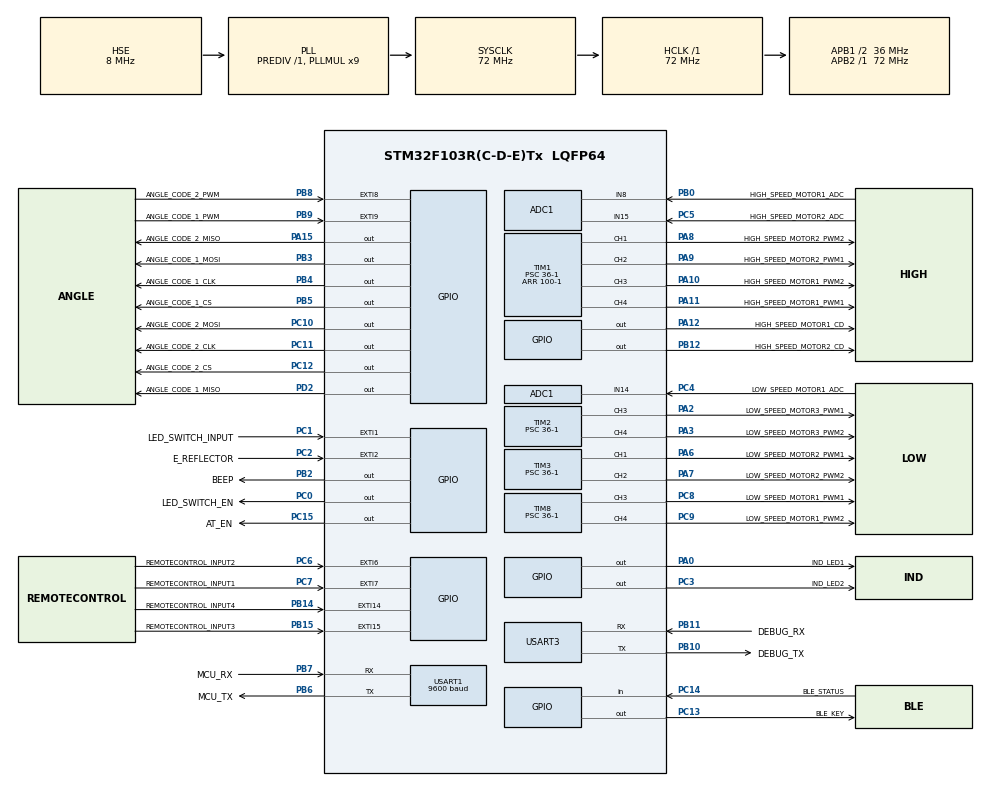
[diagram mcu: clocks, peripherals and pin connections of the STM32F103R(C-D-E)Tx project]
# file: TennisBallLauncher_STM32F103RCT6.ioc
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ADC1.Channel-11\#ChannelRegularConversion=ADC_CHANNEL_8
ADC1.Channel-12\#ChannelRegularConversion=ADC_CHANNEL_14
ADC1.Channel-13\#ChannelRegularConversion=ADC_CHANNEL_15
ADC1.ContinuousConvMode=DISABLE
ADC1.NbrOfConversion=3
ADC1.NbrOfConversionFlag=1
ADC1.Rank-11\#ChannelRegularConversion=1
ADC1.Rank-12\#ChannelRegularConversion=2
ADC1.Rank-13\#ChannelRegularConversion=3
ADC1.SamplingTime-11\#ChannelRegularConversion=ADC_SAMPLETIME_28CYCLES_5
ADC1.SamplingTime-12\#ChannelRegularConversion=ADC_SAMPLETIME_28CYCLES_5
ADC1.SamplingTime-13\#ChannelRegularConversion=ADC_SAMPLETIME_28CYCLES_5
ADC1.master=1
Dma.ADC1.1.Direction=DMA_PERIPH_TO_MEMORY
Dma.ADC1.1.Instance=DMA1_Channel1
Dma.ADC1.1.MemDataAlignment=DMA_MDATAALIGN_WORD
Dma.ADC1.1.MemInc=DMA_MINC_ENABLE
Dma.ADC1.1.Mode=DMA_CIRCULAR
Dma.ADC1.1.PeriphDataAlignment=DMA_PDATAALIGN_WORD
Dma.ADC1.1.PeriphInc=DMA_PINC_DISABLE
Dma.ADC1.1.Priority=DMA_PRIORITY_MEDIUM
Dma.Request0=USART1_RX
Dma.Request1=ADC1
Dma.USART1_RX.0.Direction=DMA_PERIPH_TO_MEMORY
Dma.USART1_RX.0.Instance=DMA1_Channel5
Dma.USART1_RX.0.MemDataAlignment=DMA_MDATAALIGN_BYTE
Dma.USART1_RX.0.MemInc=DMA_MINC_ENABLE
Dma.USART1_RX.0.Mode=DMA_CIRCULAR
Dma.USART1_RX.0.PeriphDataAlignment=DMA_PDATAALIGN_BYTE
Dma.USART1_RX.0.PeriphInc=DMA_PINC_DISABLE
Dma.USART1_RX.0.Priority=DMA_PRIORITY_LOW
Mcu.Family=STM32F1
Mcu.Name=STM32F103R(C-D-E)Tx
Mcu.Package=LQFP64
NVIC.DMA1_Channel1_IRQn=true\:0\:0\:false\:false\:true\:false\:true\:true
NVIC.DMA1_Channel5_IRQn=true\:0\:0\:false\:false\:true\:false\:true\:true
NVIC.EXTI15_10_IRQn=true\:0\:0\:false\:false\:true\:true\:true\:true
NVIC.EXTI1_IRQn=true\:0\:0\:false\:false\:true\:true\:true\:true
NVIC.EXTI2_IRQn=true\:0\:0\:false\:false\:true\:true\:true\:true
NVIC.EXTI9_5_IRQn=true\:0\:0\:false\:false\:true\:true\:true\:true
NVIC.PriorityGroup=NVIC_PRIORITYGROUP_4
NVIC.TIM6_IRQn=true\:0\:0\:false\:false\:true\:true\:true\:true
NVIC.TIM7_IRQn=true\:0\:0\:false\:false\:true\:true\:true\:true
NVIC.USART1_IRQn=true\:0\:0\:false\:false\:true\:true\:true\:true
PA0-WKUP.GPIO_Label=IND_LED1
PA0-WKUP.Signal=GPIO_Output
PA10.GPIO_Label=HIGH_SPEED_MOTOR1_PWM2
PA10.Signal=S_TIM1_CH3
PA11.GPIO_Label=HIGH_SPEED_MOTOR1_PWM1
PA11.Signal=S_TIM1_CH4
PA12.GPIO_Label=HIGH_SPEED_MOTOR1_CD
PA12.Signal=GPIO_Output
PA13.Mode=Serial_Wire
PA13.Signal=SYS_JTMS-SWDIO
PA14.Mode=Serial_Wire
PA14.Signal=SYS_JTCK-SWCLK
PA15.GPIO_Label=ANGLE_CODE_2_MISO
PA15.Signal=GPIO_Output
PA2.GPIO_Label=LOW_SPEED_MOTOR3_PWM1
PA2.Signal=S_TIM2_CH3
PA3.GPIO_Label=LOW_SPEED_MOTOR3_PWM2
PA3.Signal=S_TIM2_CH4
PA6.GPIO_Label=LOW_SPEED_MOTOR2_PWM1
PA6.Signal=S_TIM3_CH1
PA7.GPIO_Label=LOW_SPEED_MOTOR2_PWM2
PA7.Signal=S_TIM3_CH2
PA8.GPIO_Label=HIGH_SPEED_MOTOR2_PWM2
PA8.Signal=S_TIM1_CH1
PA9.GPIO_Label=HIGH_SPEED_MOTOR2_PWM1
PA9.Signal=S_TIM1_CH2
PB0.GPIO_Label=HIGH_SPEED_MOTOR1_ADC
PB0.Signal=ADCx_IN8
PB10.GPIO_Label=DEBUG_TX
PB10.Mode=Asynchronous
PB10.Signal=USART3_TX
PB11.GPIO_Label=DEBUG_RX
PB11.Mode=Asynchronous
PB11.Signal=USART3_RX
PB12.GPIO_Label=HIGH_SPEED_MOTOR2_CD
PB12.Signal=GPIO_Output
PB14.GPIO_Label=REMOTECONTROL_INPUT4
PB14.GPIO_PuPd=GPIO_PULLDOWN
PB14.Signal=GPXTI14
PB15.GPIO_Label=REMOTECONTROL_INPUT3
PB15.GPIO_PuPd=GPIO_PULLDOWN
PB15.Signal=GPXTI15
PB2.GPIO_Label=BEEP
PB2.Signal=GPIO_Output
PB3.GPIO_Label=ANGLE_CODE_1_MOSI
PB3.Signal=GPIO_Output
PB4.GPIO_Label=ANGLE_CODE_1_CLK
PB4.Signal=GPIO_Output
PB5.GPIO_Label=ANGLE_CODE_1_CS
PB5.Signal=GPIO_Output
PB6.GPIO_Label=MCU_TX
PB6.Mode=Asynchronous
PB6.Signal=USART1_TX
PB7.GPIO_Label=MCU_RX
PB7.Mode=Asynchronous
PB7.Signal=USART1_RX
PB8.GPIO_Label=ANGLE_CODE_2_PWM
PB8.GPIO_ModeDefaultEXTI=GPIO_MODE_IT_RISING_FALLING
PB8.Signal=GPXTI8
PB9.GPIO_Label=ANGLE_CODE_1_PWM
PB9.GPIO_ModeDefaultEXTI=GPIO_MODE_IT_RISING_FALLING
PB9.Signal=GPXTI9
PC0.GPIO_Label=LED_SWITCH_EN
PC0.Signal=GPIO_Output
PC1.GPIO_Label=LED_SWITCH_INPUT
PC1.GPIO_ModeDefaultEXTI=GPIO_MODE_IT_FALLING
PC1.GPIO_PuPd=GPIO_PULLUP
PC1.Signal=GPXTI1
PC10.GPIO_Label=ANGLE_CODE_2_MOSI
PC10.Signal=GPIO_Output
PC11.GPIO_Label=ANGLE_CODE_2_CLK
PC11.Signal=GPIO_Output
PC12.GPIO_Label=ANGLE_CODE_2_CS
PC12.Signal=GPIO_Output
PC13-TAMPER-RTC.GPIO_Label=BLE_KEY
PC13-TAMPER-RTC.PinState=GPIO_PIN_SET
PC13-TAMPER-RTC.Signal=GPIO_Output
PC14-OSC32_IN.GPIO_Label=BLE_STATUS
PC14-OSC32_IN.Signal=GPIO_Input
PC15-OSC32_OUT.GPIO_Label=AT_EN
PC15-OSC32_OUT.PinState=GPIO_PIN_SET
PC15-OSC32_OUT.Signal=GPIO_Output
PC2.GPIO_Label=E_REFLECTOR
PC2.GPIO_ModeDefaultEXTI=GPIO_MODE_IT_RISING
PC2.GPIO_PuPd=GPIO_PULLDOWN
PC2.Signal=GPXTI2
PC3.GPIO_Label=IND_LED2
PC3.Signal=GPIO_Output
PC4.GPIO_Label=LOW_SPEED_MOTOR1_ADC
PC4.Signal=ADCx_IN14
PC5.GPIO_Label=HIGH_SPEED_MOTOR2_ADC
PC5.Signal=ADCx_IN15
PC6.GPIO_Label=REMOTECONTROL_INPUT2
PC6.GPIO_PuPd=GPIO_PULLDOWN
PC6.Signal=GPXTI6
PC7.GPIO_Label=REMOTECONTROL_INPUT1
PC7.GPIO_PuPd=GPIO_PULLDOWN
PC7.Signal=GPXTI7
PC8.GPIO_Label=LOW_SPEED_MOTOR1_PWM1
PC8.Signal=S_TIM8_CH3
PC9.GPIO_Label=LOW_SPEED_MOTOR1_PWM2
PC9.Signal=S_TIM8_CH4
PD0-OSC_IN.Mode=HSE-External-Oscillator
PD0-OSC_IN.Signal=RCC_OSC_IN
PD1-OSC_OUT.Mode=HSE-External-Oscillator
PD1-OSC_OUT.Signal=RCC_OSC_OUT
PD2.GPIO_Label=ANGLE_CODE_1_MISO
PD2.Signal=GPIO_Output
ProjectManager.HeapSize=0x400
ProjectManager.StackSize=0x1500
ProjectManager.TargetToolchain=MDK-ARM V5.32
RCC.ADCPresc=RCC_ADCPCLK2_DIV6
RCC.AHBFreq_Value=72000000
RCC.APB1CLKDivider=RCC_HCLK_DIV2
RCC.APB1Freq_Value=36000000
RCC.APB1TimFreq_Value=72000000
RCC.APB2Freq_Value=72000000
RCC.APB2TimFreq_Value=72000000
RCC.HCLKFreq_Value=72000000
RCC.PLLMUL=RCC_PLL_MUL9
RCC.PLLSourceVirtual=RCC_PLLSOURCE_HSE
RCC.SYSCLKFreq_VALUE=72000000
RCC.SYSCLKSource=RCC_SYSCLKSOURCE_PLLCLK
RCC.USBFreq_Value=72000000
SH.ADCx_IN14.0=ADC1_IN14,IN14
SH.ADCx_IN15.0=ADC1_IN15,IN15
SH.ADCx_IN8.0=ADC1_IN8,IN8
SH.S_TIM1_CH1.0=TIM1_CH1,PWM Generation1 CH1
SH.S_TIM1_CH2.0=TIM1_CH2,PWM Generation2 CH2
SH.S_TIM1_CH3.0=TIM1_CH3,PWM Generation3 CH3
SH.S_TIM1_CH4.0=TIM1_CH4,PWM Generation4 CH4
SH.S_TIM2_CH3.0=TIM2_CH3,PWM Generation3 CH3
SH.S_TIM2_CH4.0=TIM2_CH4,PWM Generation4 CH4
SH.S_TIM3_CH1.0=TIM3_CH1,PWM Generation1 CH1
SH.S_TIM3_CH2.0=TIM3_CH2,PWM Generation2 CH2
SH.S_TIM8_CH3.0=TIM8_CH3,PWM Generation3 CH3
SH.S_TIM8_CH4.0=TIM8_CH4,PWM Generation4 CH4
TIM1.Channel-Input_Capture3_from_TI3=TIM_CHANNEL_3
TIM1.Channel-Input_Capture3_from_TI4_63=TIM_CHANNEL_3
TIM1.Channel-Input_Capture4_from_TI4=TIM_CHANNEL_4
TIM1.Channel-PWM\ Generation1\ CH1=TIM_CHANNEL_1
TIM1.Channel-PWM\ Generation2\ CH2=TIM_CHANNEL_2
TIM1.Channel-PWM\ Generation3\ CH3=TIM_CHANNEL_3
TIM1.Channel-PWM\ Generation4\ CH4=TIM_CHANNEL_4
TIM1.Period=100-1
TIM1.Prescaler=36-1
TIM2.Channel-PWM\ Generation3\ CH3=TIM_CHANNEL_3
TIM2.Channel-PWM\ Generation4\ CH4=TIM_CHANNEL_4
TIM2.Period=100-1
TIM2.Prescaler=36-1
TIM3.Channel-PWM\ Generation1\ CH1=TIM_CHANNEL_1
TIM3.Channel-PWM\ Generation2\ CH2=TIM_CHANNEL_2
TIM3.Period=100-1
TIM3.Prescaler=36-1
TIM6.Period=5000-1
TIM6.Prescaler=72-1
TIM7.Period=1000-1
TIM7.Prescaler=72-1
TIM8.Channel-PWM\ Generation3\ CH3=TIM_CHANNEL_3
TIM8.Channel-PWM\ Generation4\ CH4=TIM_CHANNEL_4
TIM8.Period=100-1
TIM8.Prescaler=36-1
USART1.BaudRate=9600
USART1.VirtualMode=VM_ASYNC
USART3.VirtualMode=VM_ASYNC
VP_TIM1_VS_ClockSourceINT.Mode=Internal
VP_TIM2_VS_ClockSourceINT.Mode=Internal
VP_TIM3_VS_ClockSourceINT.Mode=Internal
VP_TIM6_VS_ClockSourceINT.Mode=Enable_Timer
VP_TIM7_VS_ClockSourceINT.Mode=Enable_Timer
board=custom

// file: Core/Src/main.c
/* USER CODE BEGIN Header */
/**
 ******************************************************************************
 * @file           : main.c
 * @brief          : Main program body
 ******************************************************************************
 * @attention
 *
 * Copyright (c) 2024 STMicroelectronics.
 * All rights reserved.
 *
 * This software is licensed under terms that can be found in the LICENSE file
 * in the root directory of this software component.
 * If no LICENSE file comes with this software, it is provided AS-IS.
 *
 ******************************************************************************
 */
/* USER CODE END Header */
#include "main.h"
#include "adc.h"
#include "dma.h"
#include "tim.h"
#include "usart.h"
#include "gpio.h"

/* USER CODE BEGIN Includes */
#include "usart.h"
#include "myApp.h"
#include "flash.h"
#include "myBle.h"
#include "myBeep.h"

//#define log_debug printf()
/* USER CODE END Includes */

void SystemClock_Config(void);

int main(void)
{

  /* USER CODE BEGIN 1 */
  // HAL_Delay(5000); //
  /* USER CODE END 1 */

  /* MCU Configuration--------------------------------------------------------*/

  /* Reset of all peripherals, Initializes the Flash interface and the Systick. */
  HAL_Init();

  /* Configure the system clock */
  SystemClock_Config();

  /* Initialize all configured peripherals */
  MX_GPIO_Init();
  MX_DMA_Init();
  MX_ADC1_Init();
  MX_TIM1_Init();
  MX_TIM2_Init();
  MX_TIM3_Init();
  MX_USART1_UART_Init();
  MX_USART3_UART_Init();
	// debug_uart_printf("111111111 Running......\r\n");
  MX_TIM8_Init();//debug_uart_printf("2222222 Running......\r\n");
  MX_TIM7_Init();//debug_uart_printf("3333333333 Running......\r\n");
  MX_TIM6_Init();//debug_uart_printf("44444444 Running......\r\n");

  /* USER CODE BEGIN 2 */
  HAL_Delay(5000); //
  myAppTaskInit();
  debug_uart_printf("TennisBalllLauncher Running......\r\n");

//		uint8_t name_data[]="01250841180";
//	FLASH_EEPROM_Write_test(name_data,strlen(name_data),Flash_User_Name_ID);
	ble_data_init();//�����㲥name��ȡ

//	uint8_t name_data[]="01250841180";
//	FLASH_EEPROM_Write_test(name_data,strlen(name_data),Flash_User_Name_ID);

	//printf("flash_read = %d\r\n",FLASH_EEPROM_Read());

//	uint32_t rer =34;
//	uint8_t senddata[8]={1,2,3,4,5,6,7,8};
//	debug_uart_printf("flash_write\r\n");
//
//	FLASH_EEPROM_Write_test(senddata,5,Flash_User_Name_ID);
//	//FLASH_EEPROM_Write(rer);
//	//HAL_Delay(1000);
//	uint8_t dataew[100]={0};
//myBleAT_L();	ble_at_cmd_call_fun(AT_ADVI);
//ble_at_cmd_call_fun(AT_SETNAME);
//	FLASH_EEPROM_Read(dataew,8,USER_CUSTOM_DATA_FLASH);
//	///printf("flash_read22 = %d\r\n",FLASH_EEPROM_Read());
//	for(int i=0;i<8;i++)
//	{
//		debug_uart_printf(" %02x ",dataew[i]);
//	}
//

  /* USER CODE END 2 */
//test_fun();
  /* Infinite loop */
  while (1)
  {
    /* USER CODE BEGIN 3 */
     myAppTaskHandle();
  }
  /* USER CODE END 3 */
}

void SystemClock_Config(void)
{
  RCC_OscInitTypeDef RCC_OscInitStruct = {0};
  RCC_ClkInitTypeDef RCC_ClkInitStruct = {0};
  RCC_PeriphCLKInitTypeDef PeriphClkInit = {0};

  /** Initializes the RCC Oscillators according to the specified parameters
  * in the RCC_OscInitTypeDef structure.
  */
  RCC_OscInitStruct.OscillatorType = RCC_OSCILLATORTYPE_HSE;
  RCC_OscInitStruct.HSEState = RCC_HSE_ON;
  RCC_OscInitStruct.HSEPredivValue = RCC_HSE_PREDIV_DIV1;
  RCC_OscInitStruct.HSIState = RCC_HSI_ON;
  RCC_OscInitStruct.PLL.PLLState = RCC_PLL_ON;
  RCC_OscInitStruct.PLL.PLLSource = RCC_PLLSOURCE_HSE;
  RCC_OscInitStruct.PLL.PLLMUL = RCC_PLL_MUL9;
  if (HAL_RCC_OscConfig(&RCC_OscInitStruct) != HAL_OK)
  {
    Error_Handler();
  }

  /** Initializes the CPU, AHB and APB buses clocks
  */
  RCC_ClkInitStruct.ClockType = RCC_CLOCKTYPE_HCLK|RCC_CLOCKTYPE_SYSCLK
                              |RCC_CLOCKTYPE_PCLK1|RCC_CLOCKTYPE_PCLK2;
  RCC_ClkInitStruct.SYSCLKSource = RCC_SYSCLKSOURCE_PLLCLK;
  RCC_ClkInitStruct.AHBCLKDivider = RCC_SYSCLK_DIV1;
  RCC_ClkInitStruct.APB1CLKDivider = RCC_HCLK_DIV2;
  RCC_ClkInitStruct.APB2CLKDivider = RCC_HCLK_DIV1;

  if (HAL_RCC_ClockConfig(&RCC_ClkInitStruct, FLASH_LATENCY_2) != HAL_OK)
  {
    Error_Handler();
  }
  PeriphClkInit.PeriphClockSelection = RCC_PERIPHCLK_ADC;
  PeriphClkInit.AdcClockSelection = RCC_ADCPCLK2_DIV6;
  if (HAL_RCCEx_PeriphCLKConfig(&PeriphClkInit) != HAL_OK)
  {
    Error_Handler();
  }
}

void Error_Handler(void)
{
  __disable_irq();
  while (1)
  {
  }
}
